VERSION "canAnalyser demo - load via File -> Load DBC"

NS_ :

BS_:

BU_: Engine ECU ABS Dash

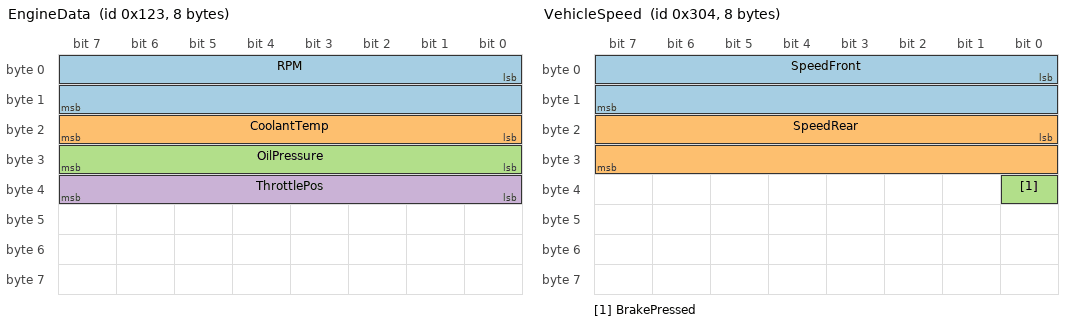
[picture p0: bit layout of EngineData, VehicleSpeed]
BO_ 291 EngineData: 8 Engine
 SG_ RPM : 0|16@1+ (0.125,0) [0|8000] "rpm" ECU
 SG_ CoolantTemp : 16|8@1+ (1,-40) [-40|215] "degC" ECU
 SG_ OilPressure : 24|8@1+ (4,0) [0|1000] "kPa" ECU
 SG_ ThrottlePos : 32|8@1+ (0.5,0) [0|100] "%" ECU

BO_ 512 ControlCmd: 3 ECU
 SG_ GearReq : 0|4@0+ (1,0) [0|8] "" Engine
 SG_ Enable : 4|1@0+ (1,0) [0|1] "" Engine

BO_ 772 VehicleSpeed: 8 ABS
 SG_ SpeedFront : 0|16@1+ (0.1,0) [0|300] "km/h" Dash
 SG_ SpeedRear : 16|16@1+ (0.1,0) [0|300] "km/h" Dash
 SG_ BrakePressed : 32|1@1+ (1,0) [0|1] "" ECU

BO_ 2000 ExtendedDiag: 8 Dash
 SG_ DiagCode : 0|16@1+ (1,0) [0|65535] "" ECU
 SG_ DiagValue : 16|16@1+ (1,0) [0|65535] "" ECU

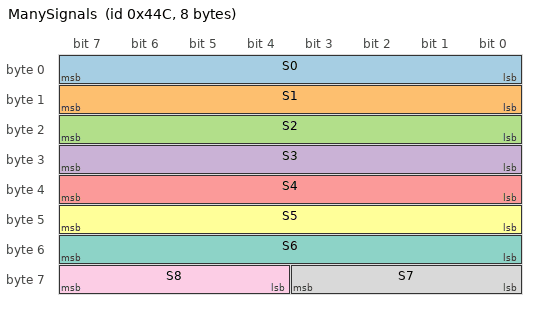
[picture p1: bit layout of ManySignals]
BO_ 1100 ManySignals: 8 ECU
 SG_ S0 : 0|8@1+ (1,0) [0|255] "" Engine
 SG_ S1 : 8|8@1+ (1,0) [0|255] "" Engine
 SG_ S2 : 16|8@1+ (1,0) [0|255] "" Engine
 SG_ S3 : 24|8@1+ (1,0) [0|255] "" Engine
 SG_ S4 : 32|8@1+ (1,0) [0|255] "" Engine
 SG_ S5 : 40|8@1+ (1,0) [0|255] "" Engine
 SG_ S6 : 48|8@1+ (1,0) [0|255] "" Engine
 SG_ S7 : 56|4@1+ (1,0) [0|15] "" Engine
 SG_ S8 : 60|4@1+ (1,0) [0|15] "" Engine

VAL_ 512 GearReq 0 "Park" 1 "Reverse" 2 "Neutral" 3 "Drive" ;
VAL_ 772 BrakePressed 0 "Released" 1 "Pressed" ;
